# STM32H7P5 register map
File version: 0.1
CPU: CM7 r1p2, little endian, MPU, FPU, 4 interrupt priority bits
Registers are 32-bit, read-write, reset 0x0 unless marked. A register's access mark holds for its fields unless they carry their own. Offsets are from the block's base; [hi:lo] are bit positions; {n}, {i} and the like mark numbered series; 'fields as' and 'values as' point back to an identical list.

## HRTIM1 (part 4 of 7) — HRTIM address block description
Base 0x42006000
Same registers: HRTIM2 0x42007000
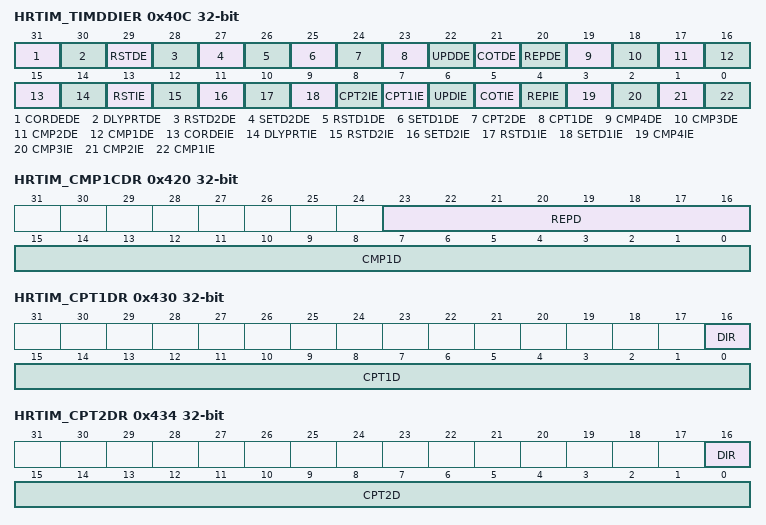
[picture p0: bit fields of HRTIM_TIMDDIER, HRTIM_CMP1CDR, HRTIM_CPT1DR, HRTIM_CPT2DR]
0x40C HRTIM_TIMDDIER — HRTIM timer D DMA interrupt enable register
  [31] CORDEDE — Crossbar override rearm delay elapsed DMA request enable
    0=Crossbar override rearm delay elapsed DMA request disabled; 1=Crossbar override rearm delay elapsed DMA request enabled
  [30] DLYPRTDE — Delayed protection DMA request enable
    0=Delayed protection DMA request disabled; 1=Delayed protection DMA request enabled
  [29] RSTDE — Reset/roll-over DMA request enable
    0=Timer x counter reset/roll-over DMA request disabled; 1=Timer x counter reset/roll-over DMA request enabled
  [28] RSTD2DE — Output 2 reset DMA request enable timer x
  [27] SETD2DE — Output 2 set DMA request enable timer x
  [26] RSTD1DE — Output 1 reset DMA request enable timer x
    0=Tx1 output reset DMA request disabled; 1=Tx1 output reset DMA request enabled
  [25] SETD1DE — Output 1 set DMA request enable timer x
    0=Tx1 output set DMA request disabled; 1=Tx1 output set DMA request enabled
  [24] CPT2DE — Capture 2 DMA request enable
  [23] CPT1DE — Capture 1 DMA request enable
    0=Capture 1 DMA request disabled; 1=Capture 1 DMA request enabled
  [22] UPDDE — Update DMA request enable
    0=Update DMA request disabled; 1=Update DMA request enabled
  [21] COTDE — Crossbar Override Trigger DMA request enable
    0=Crossbar Override Trigger DMA request disabled; 1=Crossbar Override Trigger DMA request enabled
  [20] REPDE — Repetition DMA request enable
    0=Repetition DMA request disabled; 1=Repetition DMA request enabled
  [19] CMP4DE — Compare 4 DMA request enable
  [18] CMP3DE — Compare 3 DMA request enable
  [17] CMP2DE — Compare 2 DMA request enable
  [16] CMP1DE — Compare 1 DMA request enable
    0=Compare 1 DMA request disabled; 1=Compare 1 DMA request enabled
  [15] CORDEIE — Crossbar override rearm delay elapsed interrupt enable
    0=Crossbar override rearm delay elapsed interrupts disabled; 1=Crossbar override rearm delay elapsed interrupts enabled
  [14] DLYPRTIE — Delayed protection interrupt enable
    0=Delayed protection interrupts disabled; 1=Delayed protection interrupts enabled
  [13] RSTIE — Reset/roll-over interrupt enable
    0=Timer x counter reset/roll-over interrupt disabled; 1=Timer x counter reset/roll-over interrupt enabled
  [12] RSTD2IE — Output 2 reset interrupt enable timer x
  [11] SETD2IE — Output 2 set interrupt enable timer x
  [10] RSTD1IE — Output 1 reset interrupt enable timer x
    0=Tx1 output reset interrupts disabled; 1=Tx1 output reset interrupts enabled
  [9] SETD1IE — Output 1 set interrupt enable timer x
    0=Tx1 output set interrupts disabled; 1=Tx1 output set interrupts enabled
  [8] CPT2IE — Capture interrupt enable
  [7] CPT1IE — Capture interrupt enable
    0=Capture 1 interrupts disabled; 1=Capture 1 interrupts enabled
  [6] UPDIE — Update interrupt enable
    0=Update interrupts disabled; 1=Update interrupts enabled
  [5] COTIE — Crossbar Override Trigger interrupt enable
    0=Crossbar Override Trigger interrupts disabled; 1=Crossbar Override Trigger enabled
  [4] REPIE — Repetition interrupt enable
    0=Repetition interrupts disabled; 1=Repetition interrupts enabled
  [3] CMP4IE — Compare 4 interrupt enable
  [2] CMP3IE — Compare 3 interrupt enable
  [1] CMP2IE — Compare 2 interrupt enable
  [0] CMP1IE — Compare 1 interrupt enable
    0=Compare 1 interrupt disabled; 1=Compare 1 interrupt enabled
0x410 HRTIM_CNTDR — HRTIM timer D counter register
  [15:0] CNTD — Timer x counter value
0x414 HRTIM_PERDR reset 0xFFDF — HRTIM timer D period register
  [15:0] PERD — Timer x period value
0x418 HRTIM_REPDR — HRTIM timer D repetition register
  [7:0] REPD — Timer x repetition period value
0x41C HRTIM_CMP1DR — HRTIM timer D compare 1 register
  [15:0] CMP1D — Timer x compare 1 value
0x420 HRTIM_CMP1CDR — HRTIM timer D compare 1 compound register
  [23:16] REPD — Timer x repetition value aliased from HRTIM_REPx register
  [15:0] CMP1D — Timer x compare 1 value
{0x41C+4i} HRTIM_CMP{i}DR (i=2..4) — HRTIM timer D compare {i} register
  [15:0] CMP{i}D — Timer x compare {i} value
0x430 HRTIM_CPT1DR ro — HRTIM timer D capture 1 register
  [16] DIR — Timer x capture 1 direction status
    0=timer is up-counting; 1=timer is down-counting
  [15:0] CPT1D — Timer x capture 1 value
0x434 HRTIM_CPT2DR ro — HRTIM timer D capture 2 register
  [16] DIR — Timer x capture 1 direction status
    0=timer is up-counting; 1=timer is down-counting
  [15:0] CPT2D — Timer x capture 2 value
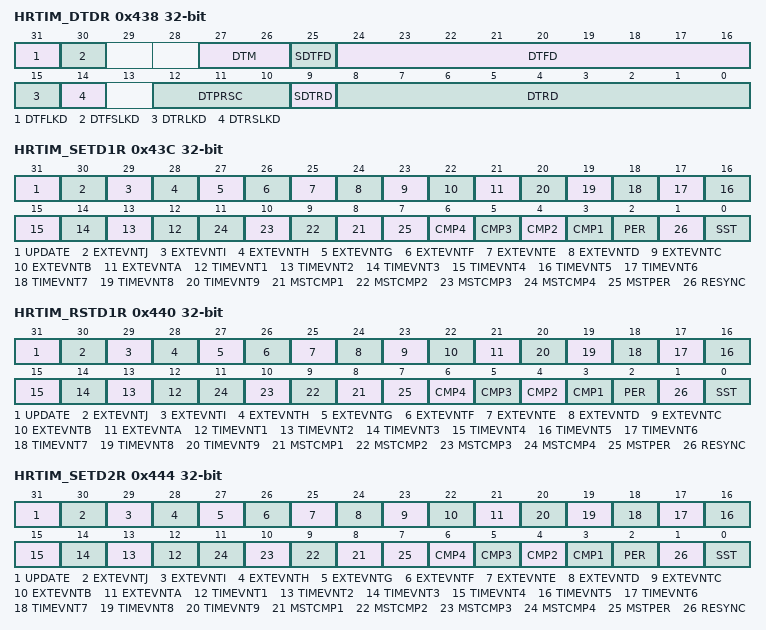
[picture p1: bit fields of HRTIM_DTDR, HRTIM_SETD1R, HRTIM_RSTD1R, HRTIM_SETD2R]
0x438 HRTIM_DTDR rw-once — HRTIM timer D deadtime register
  [31] DTFLKD — Deadtime falling lock timer x
    0=Deadtime falling value and sign is writable; 1=Deadtime falling value and sign is read-only
  [30] DTFSLKD — Deadtime falling sign lock timer x
    0=Deadtime falling sign is writable; 1=Deadtime falling sign is read-only
  [27:26] DTM rw — Deadtime mode
    0=Deadtime complementary mode; 1=Deadtime insertion mode; 2=Deadtime insertion and disarm mode
  [25] SDTFD rw — Sign deadtime falling value timer x
    0=Positive deadtime on falling edge; 1=Negative deadtime on falling edge
  [24:16] DTFD rw — Deadtime falling value timer x
  [15] DTRLKD — Deadtime rising lock timer x
    0=Deadtime rising value and sign is writable; 1=Deadtime rising value and sign is read-only
  [14] DTRSLKD — Deadtime rising sign lock timer x
    0=Deadtime rising sign is writable; 1=Deadtime rising sign is read-only
  [12:10] DTPRSC rw — Deadtime prescaler
  [9] SDTRD rw — Sign deadtime rising value timer x
    0=Positive deadtime on rising edge; 1=Negative deadtime on rising edge
  [8:0] DTRD rw — Deadtime rising value timer x
0x43C HRTIM_SETD1R — HRTIM timer D output 1 set register
  [31] UPDATE — Registers update (transfer preload to active)
  [30] EXTEVNTJ — External event J
  [29] EXTEVNTI — External event I
  [28] EXTEVNTH — External event H
  [27] EXTEVNTG — External event G
  [26] EXTEVNTF — External event F
  [25] EXTEVNTE — External event E
  [24] EXTEVNTD — External event D
  [23] EXTEVNTC — External event C
  [22] EXTEVNTB — External event B
  [21] EXTEVNTA — External event A
  [n+11] TIMEVNT{n} (n=1..9) — Timer event {n}
  [n+7] MSTCMP{n} (n=1..4) — Master compare {n}
  [7] MSTPER — Master period
  [n+2] CMP{n} (n=1..4) — Timer x compare {n}
  [2] PER — Timer x period
  [1] RESYNC — Timer A resynchronization
  [0] SST — Software set trigger
0x440 HRTIM_RSTD1R — HRTIM timer D output 1 reset register
  fields as HRTIM_SETD1R
0x444 HRTIM_SETD2R — HRTIM timer D output 2 set register
  fields as HRTIM_SETD1R
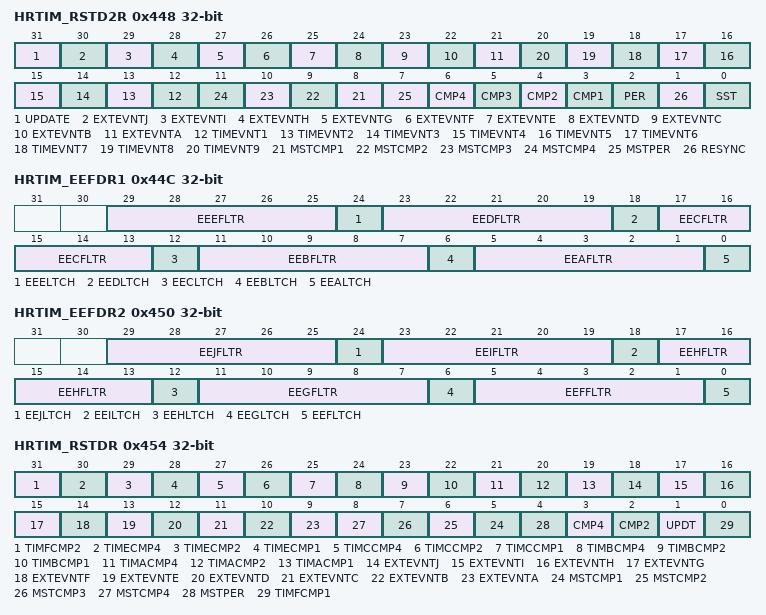
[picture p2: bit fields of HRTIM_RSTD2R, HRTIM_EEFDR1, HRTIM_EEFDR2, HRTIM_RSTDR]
0x448 HRTIM_RSTD2R — HRTIM timer D output 2 reset register
  fields as HRTIM_SETD1R
0x44C HRTIM_EEFDR1 — HRTIM timer D external event filtering register 1
  [29:25] EEEFLTR — External event E filter
  [24] EEELTCH — External event E latch
  [23:19] EEDFLTR — External event D filter
  [18] EEDLTCH — External event D latch
  [17:13] EECFLTR — External event C filter
  [12] EECLTCH — External event C latch
  [11:7] EEBFLTR — External event B filter
  [6] EEBLTCH — External event B latch
  [5:1] EEAFLTR — External event A filter
    0=No filtering; 1=Blanking from counter reset/roll-over to compare 1; 2=Blanking from counter reset/roll-over to compare 2 in up-counting mode (UDM bit reset); 3=Blanking from counter reset/roll-over to compare 3; 4=Blanking from counter reset/roll-over to compare 4 in up-counting mode (UDM bit reset); 13=Windowing from counter reset/roll-over to compare 2 in up-counting mode (UDM bit reset); 14=Windowing from counter reset/roll-over to compare 3 in up-counting mode (UDM bit reset); 15=Windowing from another timing unit: TIMWIN source (see Table136 for details) in up-counting mode (UDM bit reset); 16=Blanking from compare 1 to counter reset/roll-over (UDM bit reset); 17=Blanking from compare 2 to counter reset/roll-over (UDM bit reset); 18=Blanking from compare 1 to compare 2 (UDM bit reset); 19=Blanking from compare 3 to compare 4 (UDM bit reset); 20=Windowing from compare 1 to counter reset/roll-over; 21=Windowing from compare 2 to counter reset/roll-over; 22=Windowing from compare 1 to compare 2 (UDM bit reset); 23=Windowing from compare 3 to compare 4 (UDM bit reset); 24=TIMWIN2 source (see Table136 for details); 25=TIMWIN3 source (see Table136 for details); 26=Blanking from Period Event to Compare 1 In up-down counting mode (UDM bit set), the reset/roll-over event is conditioned to the ROM[1:0] bit field setting; 27=Blanking from Period Event to Compare 2 In up-down counting mode (UDM bit set), the reset/roll-over event is conditioned to the ROM[1:0] bit field setting
  [0] EEALTCH — External event A latch
    0=Event A is ignored if it happens during a blank, or passed through during a window; 1=Event A is latched and delayed till the end of the blanking or windowing period
0x450 HRTIM_EEFDR2 — HRTIM timer D external event filtering register 2
  [29:25] EEJFLTR — External event J filter
  [24] EEJLTCH — External event J latch
  [23:19] EEIFLTR — External event I filter
  [18] EEILTCH — External event I latch
  [17:13] EEHFLTR — External event H filter
  [12] EEHLTCH — External event H latch
  [11:7] EEGFLTR — External event G filter
  [6] EEGLTCH — External event G latch
  [5:1] EEFFLTR — External event F filter
  [0] EEFLTCH — External event F latch
0x454 HRTIM_RSTDR — HRTIM timer D reset register
  [31] TIMFCMP2 — Timer F compare 2
  [30] TIMECMP4 — Timer E compare 4
  [29] TIMECMP2 — Timer E compare 2
  [28] TIMECMP1 — Timer E compare 1
  [27] TIMCCMP4 — Timer C compare 4
  [26] TIMCCMP2 — Timer C compare 2
  [25] TIMCCMP1 — Timer C compare 1
  [24] TIMBCMP4 — Timer B compare 4
  [23] TIMBCMP2 — Timer B compare 2
  [22] TIMBCMP1 — Timer B compare 1
  [21] TIMACMP4 — Timer A compare 4
  [20] TIMACMP2 — Timer A compare 2
  [19] TIMACMP1 — Timer A compare 1
  [18] EXTEVNTJ — External event J
  [17] EXTEVNTI — External event I
  [16] EXTEVNTH — External event H
  [15] EXTEVNTG — External event G
  [14] EXTEVNTF — External event F
  [13] EXTEVNTE — External event E
  [12] EXTEVNTD — External event D
  [11] EXTEVNTC — External event C
  [10] EXTEVNTB — External event B
  [9] EXTEVNTA — External event A
  [n+4] MSTCMP{n} (n=1..4) — Master compare {n}
  [4] MSTPER — Master timer period
  [3] CMP4 — Timer D compare 4 reset
  [2] CMP2 — Timer D compare 2 reset
  [1] UPDT — Timer D update reset
  [0] TIMFCMP1 — Timer F compare 1
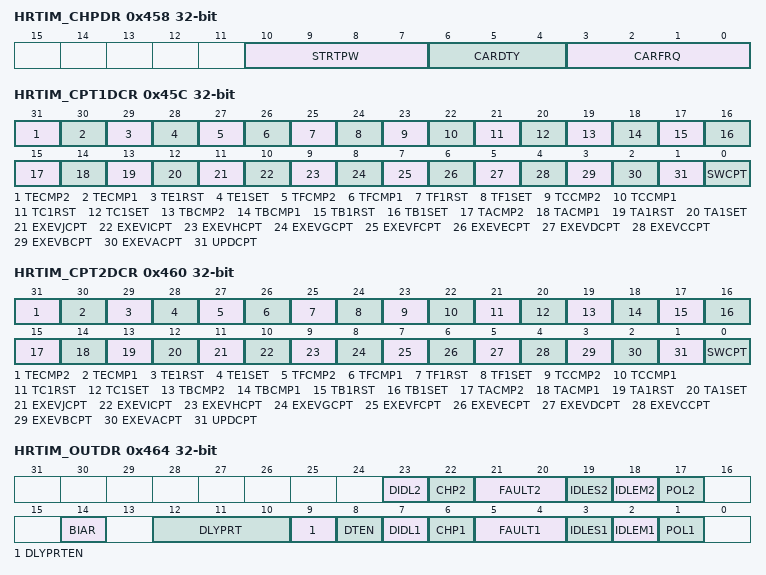
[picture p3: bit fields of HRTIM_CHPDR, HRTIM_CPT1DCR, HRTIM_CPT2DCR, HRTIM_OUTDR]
0x458 HRTIM_CHPDR — HRTIM timer D chopper register
  [10:7] STRTPW — Timer x start pulsewidth
    0=64 ns (1/15; 15=1
  [6:4] CARDTY — Timer x chopper duty cycle value
    0=0/8 (i; 7=7/8
  [3:0] CARFRQ — Timer x carrier frequency value
    0=15; 15=976
0x45C HRTIM_CPT1DCR — HRTIM timer D capture 1 control register
  [31] TECMP2 — Timer E compare 2
  [30] TECMP1 — Timer E compare 1
  [29] TE1RST — Timer E output 1 reset
  [28] TE1SET — Timer E output 1 set
  [27] TFCMP2 — Timer F compare 2
  [26] TFCMP1 — Timer F compare 1
  [25] TF1RST — Timer F output 1 reset
  [24] TF1SET — Timer F output 1 set
  [23] TCCMP2 — Timer C compare 2
  [22] TCCMP1 — Timer C compare 1
  [21] TC1RST — Timer C output 1 reset
  [20] TC1SET — Timer C output 1 set
  [19] TBCMP2 — Timer B compare 2
  [18] TBCMP1 — Timer B compare 1
  [17] TB1RST — Timer B output 1 reset
  [16] TB1SET — Timer B output 1 set
  [15] TACMP2 — Timer A compare 2
    0=No action; 1=Timer A compare 2 triggers capture 1
  [14] TACMP1 — Timer A compare 1
    0=No action; 1=Timer A compare 1 triggers capture 1
  [13] TA1RST — Timer B output 1 reset
    0=No action; 1=Capture 1 is triggered by TA1 output active to inactive transition
  [12] TA1SET — Timer B output 1 set
    0=No action; 1=Capture 1 is triggered by TA1 output inactive to active transition
  [11] EXEVJCPT — External event J capture
  [10] EXEVICPT — External event I capture
  [9] EXEVHCPT — External event H capture
  [8] EXEVGCPT — External event G capture
  [7] EXEVFCPT — External event F capture
  [6] EXEVECPT — External event E capture
  [5] EXEVDCPT — External event D capture
  [4] EXEVCCPT — External event C capture
  [3] EXEVBCPT — External event B capture
  [2] EXEVACPT — External event A capture
    0=No action; 1=The external event A triggers the capture 1
  [1] UPDCPT — Update capture
    0=No action; 1=The update event triggers the capture 1
  [0] SWCPT — Software capture
    0=No action; 1=This bit forces the capture 1 by software
0x460 HRTIM_CPT2DCR — HRTIM timer D capture 2 control register
  [31] TECMP2 — Timer E compare 2
  [30] TECMP1 — Timer E compare 1
  [29] TE1RST — Timer E output 1 reset
  [28] TE1SET — Timer E output 1 set
  [27] TFCMP2 — Timer F compare 2
  [26] TFCMP1 — Timer F compare 1
  [25] TF1RST — Timer F output 1 reset
  [24] TF1SET — Timer F output 1 set
  [23] TCCMP2 — Timer C compare 2
  [22] TCCMP1 — Timer C compare 1
  [21] TC1RST — Timer C output 1 reset
  [20] TC1SET — Timer C output 1 set
  [19] TBCMP2 — Timer B compare 2
  [18] TBCMP1 — Timer B compare 1
  [17] TB1RST — Timer B output 1 reset
  [16] TB1SET — Timer B output 1 set
  [15] TACMP2 — Timer A compare 2
    0=No action; 1=Timer A compare 2 triggers capture 2
  [14] TACMP1 — Timer A compare 1
    0=No action; 1=Timer A compare 1 triggers capture 2
  [13] TA1RST — Timer B output 1 reset
    0=No action; 1=Capture 2 is triggered by TA1 output active to inactive transition
  [12] TA1SET — Timer B output 1 set
    0=No action; 1=Capture 2 is triggered by TA1 output inactive to active transition
  [11] EXEVJCPT — External event J capture
  [10] EXEVICPT — External event I capture
  [9] EXEVHCPT — External event H capture
  [8] EXEVGCPT — External event G capture
  [7] EXEVFCPT — External event F capture
  [6] EXEVECPT — External event E capture
  [5] EXEVDCPT — External event D capture
  [4] EXEVCCPT — External event C capture
  [3] EXEVBCPT — External event B capture
  [2] EXEVACPT — External event A capture
    0=No action; 1=The external event A triggers the capture 2
  [1] UPDCPT — Update capture
    0=No action; 1=The update event triggers the capture 2
  [0] SWCPT — Software capture
    0=No action; 1=This bit forces the capture 2 by software
0x464 HRTIM_OUTDR — HRTIM timer D output register
  [23] DIDL2 — Output 2 deadtime upon burst mode Idle entry
    0=The programmed Idle state is applied immediately to the output 2; 1=Deadtime (inactive level) is inserted on output 2 before entering the idle mode
  [22] CHP2 — Output 2 chopper enable
    0=Output signal is not altered; 1=Output signal is chopped by a carrier signal
  [21:20] FAULT2 — Output 2 fault state
    0=No action: the output is not affected by the fault input and stays in run mode; 1=Active; 2=Inactive; 3=High-Z
  [19] IDLES2 — Output 2 idle state
    0=Inactive; 1=Active
  [18] IDLEM2 — Output 2 idle mode
    0=No action: the output is not affected by the burst mode operation; 1=The output is in idle state when requested by the burst mode controller
  [17] POL2 — Output 2 polarity
    0=Positive polarity (output active high); 1=Negative polarity (output active low)
  [14] BIAR — Balanced Idle Automatic Resume
    0=Disabled; 1=Enabled
  [12:10] DLYPRT — Delayed protection
    0=Output 1 delayed idle on external event H; 1=Output 2 delayed idle on external event H; 2=Output 1 and output 2 delayed idle on external event H; 3=Balanced idle on external event H; 4=Output 1 delayed idle on external event I; 5=Output 2 delayed idle on external event I; 6=Output 1 and output 2 delayed idle on external event I; 7=Balanced idle on external event I
  [9] DLYPRTEN — Delayed protection enable
    0=No action; 1=Delayed protection is enabled, as per DLYPRT[2:0] bits
  [8] DTEN — Deadtime enable
    0=Output 1 and output 2 signals are independent; 1=Deadtime is inserted between output 1 and output 2 (reference signal is output 1 signal generator)
  [7] DIDL1 — Output 1 deadtime upon burst mode idle entry
    0=The programmed idle state is applied immediately to the output 1; 1=Deadtime (inactive level) is inserted on output 1 before entering the idle mode
  [6] CHP1 — Output 1 chopper enable
    values as CHP2
  [5:4] FAULT1 — Output 1 fault state
    values as FAULT2
  [3] IDLES1 — Output 1 Idle State
    0=Inactive; 1=Active
  [2] IDLEM1 — Output 1 Idle mode
    values as IDLEM2
  [1] POL1 — Output 1 polarity
    values as POL2
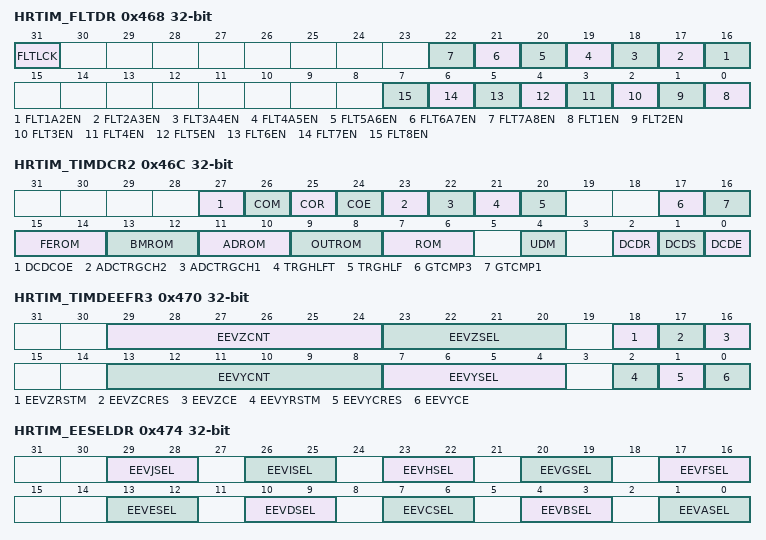
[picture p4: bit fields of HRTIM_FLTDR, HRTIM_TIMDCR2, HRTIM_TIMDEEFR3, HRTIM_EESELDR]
0x468 HRTIM_FLTDR rw-once — HRTIM timer D fault register
  [31] FLTLCK — Fault sources lock
    0=FLT1EN; 1=FLT1EN
  [n+15] FLT{n}A{n+1}EN rw (n=1..7) — Fault {n} AND Fault {n+1} enable
    0=Fault {n} AND Fault {n+1} ignored; 1=HRTIM outputs disabled when both Fault {n} AND Fault {n+1} inputs are active
  [n-1] FLT{n}EN rw (n=1..8) — Fault {n} enable
    0=Fault {n} input ignored; 1=Fault {n} input is active and disables HRTIM outputs
0x46C HRTIM_TIMDCR2 — HRTIM timer D control register 2
  [27] DCDCOE — Dual channel DAC crossbar override enable
    0=Dual Channel DAC Crossbar Override disabled; 1=Dual Channel DAC Crossbar Override enabled
  [26] COM — Crossbar override mode
    0=Cycle-by-cycle mode; 1=latched mode
  [25] COR wo — Crossbar override rearm
  [24] COE — Crossbar override enable
    0=Crossbar override disabled; 1=Crossbar override enabled
  [23] ADCTRGCH2 — ADC trigger for channel 2
    0=ADC triggers generated for both Channel 1 and Channel 2 active phases; 1=ADC triggers generated only when Channel 2 is active (in push-pull mode)
  [22] ADCTRGCH1 — ADC trigger for channel 1
    0=ADC triggers generated for both Channel 1 and Channel 2 active phases; 1=ADC triggers generated only when Channel 1 is active (in push-pull mode)
  [21] TRGHLFT — Triggered-half timeout mode
    0=No timeout event generated; 1=timeout event generated
  [20] TRGHLF — Triggered-half mode
    0=CMP2 register is written by the user only (standard compare mode); 1=CMP2 value is set by hardware as soon as a capture 1 event occurs
  [17] GTCMP3 — Greater than compare 3 PWM mode
    0=The compare 3 event is generated when the counter is equal to the compare value (compare match mode); 1=The compare 3 event is generated when the counter is greater than the compare value
  [16] GTCMP1 — Greater than compare 1 PWM mode
    0=The compare 1 event is generated when the counter is equal to the compare value (compare match mode); 1=The compare 1 event is generated when the counter is greater than the compare value
  [15:14] FEROM — Fault and event roll-over mode
    0=Event generated when the counter is equal to 0 or to HRTIM_PERxR value; 1=Event generated when the counter is equal to 0; 2=Event generated when the counter is equal to HRTIM_PERxR
  [13:12] BMROM — Burst mode roll-over mode
    values as FEROM
  [11:10] ADROM — ADC roll-over mode
    values as FEROM
  [9:8] OUTROM — Output roll-over mode
    values as FEROM
  [7:6] ROM — Roll-over mode
    values as FEROM
  [4] UDM — Up-Down mode
    0=The counter is operating in up-counting mode; 1=The counter is operating in up-down counting mode
  [2] DCDR — Dual channel DAC reset trigger
    0=The trigger is generated on counter reset or roll-over event; 1=The trigger is generated on output 1 set event
  [1] DCDS — Dual channel DAC Step trigger
    0=The trigger is generated on compare 2 event; 1=The trigger is generated on output 1 reset event
  [0] DCDE — Dual channel DAC trigger enable
    0=Dual channel DAC trigger disabled; 1=Dual channel DAC trigger enabled
0x470 HRTIM_TIMDEEFR3 — HRTIM timer D external event filtering register 3
  [29:24] EEVZCNT — External event Z counter
  [23:20] EEVZSEL — External event Z selection
    0=External event A is used as external event Z source; 1=External event B is used as external event Z source
  [18] EEVZRSTM — External event Z reset mode
    0=External event counter Z is reset on each reset / roll-over event; 1=External event counter Z is reset on each reset / roll-over event only if no event occurs during last counting period
  [17] EEVZCRES — External event Z counter reset
    0=No action; 1=External event counter Z counter is reset
  [16] EEVZCE — External event Z counter enable
    0=External event Z counter disabled; 1=External event Z counter enabled
  [13:8] EEVYCNT — External event Y counter
  [7:4] EEVYSEL — External event Y Selection
    0=External event A is used as external event Y source; 1=External event B is used as external event Y source
  [2] EEVYRSTM — External event Y reset mode
    0=External event counter Y is reset on each reset / roll-over event; 1=External event counter Y is reset on each reset / roll-over event only if no event occurs during last counting period
  [1] EEVYCRES — External event Y counter reset
    0=No action; 1=External event counter Y is reset
  [0] EEVYCE — External event Y counter enable
    0=External event Y counter disabled; 1=External event Y counter enabled
0x474 HRTIM_EESELDR — HRTIM timer D external event selection register
  [29:28] EEVJSEL — External event J selection
    0=EEVJ is connected to EEV10; 1=EEVJ is connected to EEV14; 2=EEVJ is connected to (EEV10 AND EEV11); 3=EEVJ is connected to (EEV10 AND EEV14)
  [26:25] EEVISEL — External event I selection
    0=EEVI is connected to EEV9; 1=EEVI is connected to EEV13; 2=EEVI is connected to (EEV9 AND EEV10); 3=EEVI is connected to (EEV9 AND EEV13)
  [23:22] EEVHSEL — External event H selection
    0=EEVH is connected to EEV8; 1=EEVH is connected to EEV12; 2=EEVH is connected to (EEV8 AND EEV9); 3=EEVH is connected to (EEV8 AND EEV12)
  [20:19] EEVGSEL — External event G selection
    0=EEVG is connected to EEV7; 1=EEVG is connected to EEV11; 2=EEVG is connected to (EEV7 AND EEV8); 3=EEVG is connected to (EEV7 AND EEV11)
  [17:16] EEVFSEL — External event F selection
    0=EEVF is connected to EEV6; 1=EEVF is connected to EEV16; 2=EEVF is connected to (EEV6 AND EEV7); 3=EEVF is connected to (EEV6 AND EEV16)
  [13:12] EEVESEL — External event E selection
    0=EEVE is connected to EEV5; 1=EEVE is connected to EEV15; 2=EEVE is connected to (EEV5 AND EEV6); 3=EEVE is connected to (EEV5 AND EEV15)
  [10:9] EEVDSEL — External event D selection
    0=EEVD is connected to EEV4; 1=EEVD is connected to EEV14; 2=EEVD is connected to (EEV4 AND EEV5); 3=EEVD is connected to (EEV4 AND EEV14)
  [7:6] EEVCSEL — External event C selection
    0=EEVC is connected to EEV3; 1=EEVC is connected to EEV13; 2=EEVC is connected to (EEV3 AND EEV4); 3=EEVC is connected to (EEV3 AND EEV13)
  [4:3] EEVBSEL — External event B selection
    0=EEVB is connected to EEV2; 1=EEVB is connected to EEV12; 2=EEVB is connected to (EEV2 AND EEV3); 3=EEVB is connected to (EEV2 AND EEV12)
  [1:0] EEVASEL — External event A selection
    0=EEVA is connected to EEV1; 1=EEVA is connected to EEV11; 2=EEVA is connected to (EEV1 AND EEV2); 3=EEVA is connected to (EEV1 AND EEV11)
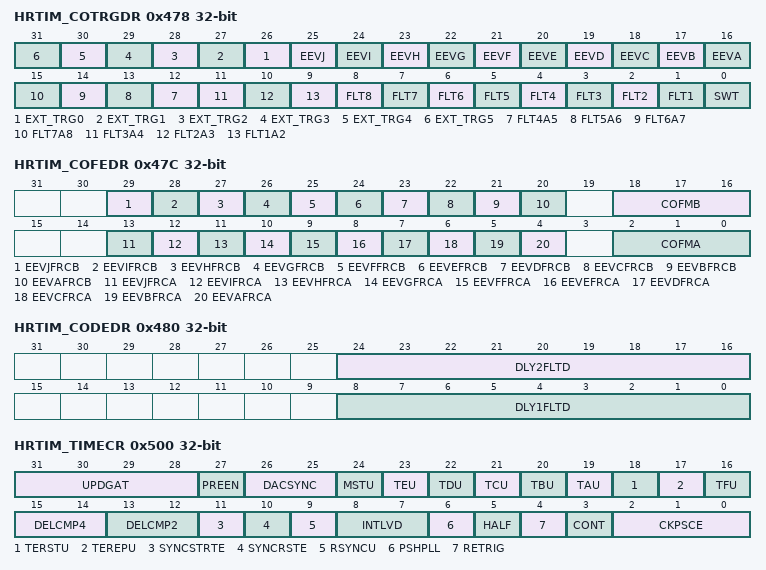
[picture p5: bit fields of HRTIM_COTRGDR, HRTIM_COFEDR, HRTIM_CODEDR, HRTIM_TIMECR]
0x478 HRTIM_COTRGDR — HRTIM timer D crossbar override trigger register
  [n+26] EXT_TRG{n} (n=0..5) — External trigger {n}
    0=External trigger {n} ignored; 1=External trigger {n} enabled
  [25] EEVJ — EEVJ trigger
    0=EEVJ input trigger ignored; 1=EEVJ input trigger enabled
  [24] EEVI — EEVI trigger
    0=EEVI input trigger ignored; 1=EEVI input trigger enabled
  [23] EEVH — EEVH trigger
    0=EEVH input trigger ignored; 1=EEVH input trigger enabled
  [22] EEVG — EEVG trigger
    0=EEVG input trigger ignored; 1=EEVG input trigger enabled
  [21] EEVF — EEVF trigger
    0=EEVF input trigger ignored; 1=EEVF input trigger enabled
  [20] EEVE — EEVE trigger
    0=EEVE input trigger ignored; 1=EEVE input trigger enabled
  [19] EEVD — EEVD trigger
    0=EEVD input trigger ignored; 1=EEVD input trigger enabled
  [18] EEVC — EEVC trigger
    0=EEVC input trigger ignored; 1=EEVC input trigger enabled
  [17] EEVB — EEVB trigger
    0=EEVB input trigger ignored; 1=EEVB input trigger enabled
  [16] EEVA — EEVA trigger
    0=EEVA input trigger ignored; 1=EEVA input trigger enabled
  [n+8] FLT{n}A{n+1} (n=4..7) — FLT{n}A{n+1} trigger
    0=(Fault {n} AND Fault {n+1}) trigger ignored; 1=(Fault {n} AND Fault {n+1}) trigger enabled
  [11] FLT3A4 — FLT2A3 trigger
    0=(Fault 3 AND Fault 4) trigger ignored; 1=(Fault 3 AND Fault 4) trigger enabled
  [10] FLT2A3 — FLT2A3 trigger
    0=(Fault 2 AND Fault 3) trigger ignored; 1=(Fault 2 AND Fault 3) trigger enabled
  [9] FLT1A2 — FLT1A2 trigger
    0=(Fault 1 AND Fault 2) trigger ignored; 1=(Fault 1 AND Fault 2) trigger enabled
  [n] FLT{n} (n=1..8) — FLT{n} trigger
    0=Fault {n} input trigger ignored; 1=Fault {n} input trigger enabled
  [0] SWT — Software trigger
    0=No action; 1=Crossbar override software trigger
0x47C HRTIM_COFEDR — HRTIM timer D crossbar override forcing event register
  [29] EEVJFRCB — External event J forces output B
    0=No action; 1=Output B is forced to the active levelwhen External Event J is active
  [28] EEVIFRCB — External event I forces output B
    0=No action; 1=Output B is forced to the active levelwhen External Event I is active
  [27] EEVHFRCB — External event H forces output B
    0=No action; 1=Output B is forced to the active levelwhen External Event H is active
  [26] EEVGFRCB — External event G forces output B
    0=No action; 1=Output B is forced to the active levelwhen External Event G is active
  [25] EEVFFRCB — External event F forces output B
    0=No action; 1=Output B is forced to the active levelwhen External Event F is active
  [24] EEVEFRCB — External event E forces output B
    0=No action; 1=Output B is forced to active levelwhen External Event E is active
  [23] EEVDFRCB — External event D forces output B
    0=No action; 1=Output B is forced to the active levelwhen External Event D is active
  [22] EEVCFRCB — External event C forces output B
    0=No action; 1=Output B is forced to the active levelwhen External Event C is active
  [21] EEVBFRCB — External event B forces output B
    0=No action; 1=Output B is forced to the active levelwhen External Event B is active
  [20] EEVAFRCB — External event A forces output B
    0=No action; 1=Output B is forced to active levelwhen External Event A is active
  [18:16] COFMB — Crossbar override force mode output B
    0=Delayed 1 fault; 1=Delayed 2 fault; 2=Output B forced to inactive level; 3=Output B forced to active level; 4=Output B forced on events, as defined with EEVAFRCB
  [13] EEVJFRCA — External event J forces output A
    0=No action; 1=Output A is forced to the active levelwhen External Event J is active
  [12] EEVIFRCA — External event I forces output A
    0=No action; 1=Output A is forced to the active levelwhen External Event I is active
  [11] EEVHFRCA — External event H forces output A
    0=No action; 1=Output A is forced to the active levelwhen External Event H is active
  [10] EEVGFRCA — External event G forces output A
    0=No action; 1=Output A is forced to the active levelwhen External Event G is active
  [9] EEVFFRCA — External event F forces output A
    0=No action; 1=Output A is forced to the active levelwhen External Event F is active
  [8] EEVEFRCA — External event E forces output A
    0=No action; 1=Output A is forced to active levelwhen External Event E is active
  [7] EEVDFRCA — External event D forces output A
    0=No action; 1=Output A is forced to the active levelwhen External Event D is active
  [6] EEVCFRCA — External event C forces output A
    0=No action; 1=Output A is forced to the active levelwhen External Event C is active
  [5] EEVBFRCA — External event B forces output A
    0=No action; 1=Output A is forced to the active levelwhen External Event B is active
  [4] EEVAFRCA — External event A forces output A
    0=No action; 1=Output A is forced to active levelwhen External Event A is active
  [2:0] COFMA — Crossbar override force mode output A
    0=Delayed 1 fault; 1=Delayed 2 fault; 2=Output A forced to inactive level; 3=Output A forced to active level; 4=Output A forced on events, as defined with EEVAFRCA
0x480 HRTIM_CODEDR — HRTIM timer D crossbar override delayed fault event register
  [24:16] DLY2FLTD — Delayed 2 Fault duration
  [8:0] DLY1FLTD — Delayed 1 Fault duration
0x500 HRTIM_TIMECR — HRTIM timer E control register
  [31:28] UPDGAT — Update gating
    0=The update occurs independently from the DMA burst transfer; 1=The update occurs when the DMA burst transfer is completed; 2=The update occurs on the update event following the DMA burst transfer completion; 3=The update occurs on a rising edge on hrtim_upd_en1; 4=The update occurs on a rising edge on hrtim_upd_en2; 5=The update occurs on a rising edge on hrtim_upd_en3; 6=The update occurs on the update event following a rising edge on hrtim_upd_en1; 7=The update occurs on the update event following a rising edge on hrtim_upd_en2; 8=The update occurs on the update event following a rising edge on hrtim_upd_en3
  [27] PREEN — Preload enable
    0=Preload disabled: the write access is directly done into the active register; 1=Preload enabled: the write access is done into the preload register
  [26:25] DACSYNC — DAC synchronization
    0=No DAC trigger generated; 1=Trigger generated on hrtim_dac_trg1; 2=Trigger generated on hrtim_dac_trg2; 3=Trigger generated on hrtim_dac_trg3
  [24] MSTU — Master timer update
    0=Update by master timer disabled; 1=Update by master timer enabled
  [23] TEU — Timer E update
    0=Update by timer E disabled; 1=Update by timer E enabled
  [22] TDU — Timer D update
    0=Update by timer D disabled; 1=Update by timer D enabled
  [21] TCU — Timer C update
    0=Update by timer C disabled; 1=Update by timer C enabled
  [20] TBU — Timer B update
    0=Update by timer B disabled; 1=Update by timer B enabled
  [19] TAU — Timer A update
    0=Update by timer A disabled; 1=Update by timer A enabled
  [18] TERSTU — Timer x reset update
    0=Update by timer x reset / roll-over disabled; 1=Update by timer x reset / roll-over enabled
  [17] TEREPU — Timer x repetition update
    0=Update on repetition disabled; 1=Update on repetition enabled
  [16] TFU — Timer F update
    0=Update by timer F disabled; 1=Update by timer F enabled
  [15:14] DELCMP4 — CMP4 auto-delayed mode
    0=CMP4 register is always active (standard compare mode); 1=CMP4 value is recomputed and is active following a capture 2 event; 2=CMP4 value is recomputed and is active following a capture 2 event, or is recomputed and active after Compare 1 match (timeout function if capture 2 event is missing); 3=CMP4 value is recomputed and is active following a capture 2 event, or is recomputed and active after Compare 3 match (timeout function if capture event is missing)
  [13:12] DELCMP2 — CMP2 auto-delayed mode
    0=CMP2 register is always active (standard compare mode); 1=CMP2 value is recomputed and is active following a capture 1 event; 2=CMP2 value is recomputed and is active following a capture 1 event, or is recomputed and active after compare 1 match (timeout function if capture event is missing); 3=CMP2 value is recomputed and is active following a capture 1 event, or is recomputed and active after compare 3 match (timeout function if capture event is missing)
  [11] SYNCSTRTE — Synchronization starts timer x
    0=No effect on timer x; 1=A synchronization input event starts the timer x
  [10] SYNCRSTE — Synchronization resets timer x
    0=No effect on timer x; 1=A synchronization input event resets the timer x
  [9] RSYNCU — Re-synchronized update
    0=The update coming from adjacent timers (when MSTU, TAU, TBU, TCU, TDU, TEU, TFU bit is set) or from a software update (TxSWU bit) is taken into account immediately; 1=The update coming from adjacent timers (when MSTU, TAU, TBU, TCU, TDU, TEU, TFU bit is set) or from a software update (TxSWU bit) is taken into account on the following reset/roll-over event
  [8:7] INTLVD — Interleaved mode
    0=Interleaved mode disabled; 1=Triple interleaved mode: when HRTIM_PERxR register is written, the HRTIM_CMP1xR active register is automatically updated with HRTIM_PERxR/3 value, and the HRTIM_CMP2xR active register is automatically updated with 2x (HRTIM_PERxR/3) value; 2=Quad interleaved mode: when HRTIM_PERxR register is written, the HRTIM_CMP1xR active register is automatically updated with HRTIM_PERxR/4 value, the HRTIM_CMP2xR active register is automatically updated with HRTIM_PERxR/2 value and the HRTIM_CMP3xR active register is automatically updated with 3x (HRTIM_PERxR/4) value; 3=Interleaved mode disabled
  [6] PSHPLL — Push-pull mode enable
    0=Push-pull mode disabled; 1=Push-pull mode enabled
  [5] HALF — Half mode enable
    0=Half mode disabled; 1=Half mode enabled
  [4] RETRIG — Re-triggerable mode
    0=The timer is not re-triggerable: a counter reset is done if the counter is stopped (period elapsed in single-shot mode or counter stopped in continuous mode); 1=The timer is re-triggerable: a counter reset is done whatever the counter state
  [3] CONT — Continuous mode
    0=The timer operates in single-shot mode and stops when it reaches TIMxPER value; 1=The timer operates in continuous mode and rolls over to zero when it reaches TIMxPER value
  [2:0] CKPSCE — HRTIM timer x clock prescaler
